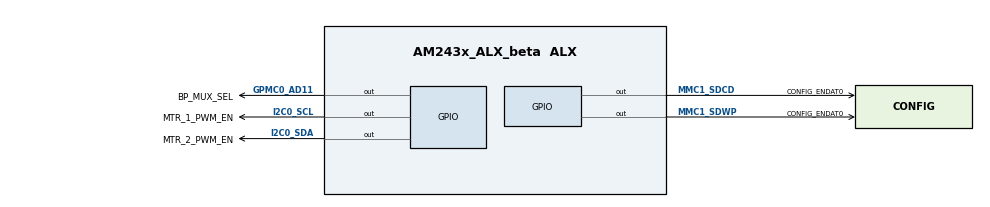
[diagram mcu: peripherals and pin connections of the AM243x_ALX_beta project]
/**
 * @cliArgs --device "AM243x_ALX_beta" --package "ALX" --part "ALX" --context "r5fss0-0" --product "MOTOR_CONTROL_SDK@09.01.00"
 * @versions {"tool":"1.19.0+3426"}
 */

/**
 * Import the modules used in this configuration.
 */
const epwm            = scripting.addModule("/drivers/epwm/epwm", {}, false);
const epwm1           = epwm.addInstance();
const epwm2           = epwm.addInstance();
const epwm3           = epwm.addInstance();
const gpio            = scripting.addModule("/drivers/gpio/gpio", {}, false);
const gpio1           = gpio.addInstance();
const gpio2           = gpio.addInstance();
const gpio3           = gpio.addInstance();
const ipc             = scripting.addModule("/drivers/ipc/ipc");
const mcspi           = scripting.addModule("/drivers/mcspi/mcspi", {}, false);
const mcspi1          = mcspi.addInstance();
const pruicss         = scripting.addModule("/drivers/pruicss/pruicss", {}, false);
const pruicss1        = pruicss.addInstance();
const debug_log       = scripting.addModule("/kernel/dpl/debug_log");
const mpu_armv7       = scripting.addModule("/kernel/dpl/mpu_armv7", {}, false);
const mpu_armv71      = mpu_armv7.addInstance();
const mpu_armv72      = mpu_armv7.addInstance();
const mpu_armv73      = mpu_armv7.addInstance();
const mpu_armv74      = mpu_armv7.addInstance();
const mpu_armv75      = mpu_armv7.addInstance();
const mpu_armv76      = mpu_armv7.addInstance();
const mpu_armv77      = mpu_armv7.addInstance();
const mpu_armv78      = mpu_armv7.addInstance();
const mpu_armv79      = mpu_armv7.addInstance();
const mpu_armv710     = mpu_armv7.addInstance();
const mpu_armv711     = mpu_armv7.addInstance();
const mpu_armv712     = mpu_armv7.addInstance();
const mpu_armv713     = mpu_armv7.addInstance();
const default_linker  = scripting.addModule("/memory_configurator/default_linker", {}, false);
const default_linker1 = default_linker.addInstance();
const general         = scripting.addModule("/memory_configurator/general", {}, false);
const general1        = general.addInstance();
const region          = scripting.addModule("/memory_configurator/region", {}, false);
const region1         = region.addInstance();
const section         = scripting.addModule("/memory_configurator/section", {}, false);
const section1        = section.addInstance();
const section2        = section.addInstance();
const section3        = section.addInstance();
const section4        = section.addInstance();
const section5        = section.addInstance();
const section6        = section.addInstance();
const section7        = section.addInstance();
const section8        = section.addInstance();
const section9        = section.addInstance();
const section10       = section.addInstance();
const section11       = section.addInstance();
const section12       = section.addInstance();
const section13       = section.addInstance();
const section14       = section.addInstance();
const section15       = section.addInstance();
const section16       = section.addInstance();
const section17       = section.addInstance();
const section18       = section.addInstance();
const section19       = section.addInstance();
const section20       = section.addInstance();
const endat           = scripting.addModule("/position_sense/endat", {}, false);
const endat1          = endat.addInstance();
const pru_ipc         = scripting.addModule("/pru_io/pru_ipc/pru_ipc", {}, false);
const pru_ipc1        = pru_ipc.addInstance();

/**
 * Write custom configuration values to the imported modules.
 */
epwm1.$name            = "EPWM0";
epwm1.EPWM.$assign     = "EHRPWM2";
epwm1.EPWM.SYNCO.$used = false;
epwm1.EPWM.SYNCI.$used = false;

epwm2.$name            = "EPWM1";
epwm2.EPWM.$assign     = "EHRPWM1";
epwm2.EPWM.SYNCO.$used = false;
epwm2.EPWM.SYNCI.$used = false;

epwm3.$name            = "EPWM2";
epwm3.EPWM.$assign     = "EHRPWM0";
epwm3.EPWM.SYNCO.$used = false;
epwm3.EPWM.SYNCI.$used = false;

gpio1.$name                = "MTR_1_PWM_EN";
gpio1.pinDir               = "OUTPUT";
gpio1.GPIO.gpioPin.$assign = "I2C0_SCL";

gpio2.$name                = "MTR_2_PWM_EN";
gpio2.pinDir               = "OUTPUT";
gpio2.GPIO.gpioPin.$assign = "I2C0_SDA";

gpio3.$name                = "BP_MUX_SEL";
gpio3.pinDir               = "OUTPUT";
gpio3.GPIO.gpioPin.$assign = "GPMC0_AD11";

ipc.r5fss0_1 = "notify";
ipc.r5fss1_0 = "notify";
ipc.r5fss1_1 = "NONE";
ipc.m4fss0_0 = "notify";

mcspi1.$name                 = "CONFIG_MCSPI0";
mcspi1.pinMode               = 3;
mcspi1.inputSelect           = "0";
mcspi1.dpe0                  = "DISABLE";
mcspi1.dpe1                  = "ENABLE";
mcspi1.intrEnable            = "POLLED";
mcspi1.SPI.$assign           = "SPI0";
mcspi1.mcspiChannel[0].$name = "CONFIG_MCSPI_CH0";
mcspi1.child.$name           = "drivers_mcspi_v0_mcspi_v0_template0";

const udma        = scripting.addModule("/drivers/udma/udma", {}, false);
const udma1       = udma.addInstance({}, false);
udma1.$name       = "CONFIG_UDMA0";
mcspi1.udmaDriver = udma1;

debug_log.enableCssLog = false;

mpu_armv71.$name             = "CONFIG_MPU_REGION0";
mpu_armv71.size              = 31;
mpu_armv71.attributes        = "Device";
mpu_armv71.accessPermissions = "Supervisor RD+WR, User RD";
mpu_armv71.allowExecute      = false;

mpu_armv72.$name             = "CONFIG_MPU_REGION1";
mpu_armv72.accessPermissions = "Supervisor RD+WR, User RD";
mpu_armv72.size              = 16;
mpu_armv72.attributes        = "NonCached";

mpu_armv73.$name             = "CONFIG_MPU_REGION2";
mpu_armv73.baseAddr          = 0x41010000;
mpu_armv73.accessPermissions = "Supervisor RD+WR, User RD";
mpu_armv73.size              = 16;
mpu_armv73.attributes        = "NonCached";

mpu_armv74.$name             = "CONFIG_MPU_REGION3";
mpu_armv74.accessPermissions = "Supervisor RD+WR, User RD";
mpu_armv74.baseAddr          = 0x70000000;
mpu_armv74.size              = 21;

mpu_armv75.$name        = "CONFIG_MPU_REGION4";
mpu_armv75.baseAddr     = 0x60000000;
mpu_armv75.size         = 28;
mpu_armv75.attributes   = "Device";
mpu_armv75.allowExecute = false;

mpu_armv76.$name        = "CONFIG_MPU_REGION5_GPIO";
mpu_armv76.baseAddr     = 0x600000;
mpu_armv76.size         = 19;
mpu_armv76.attributes   = "Device";
mpu_armv76.allowExecute = false;

mpu_armv77.$name        = "CONFIG_MPU_REGION6_ICSSG0";
mpu_armv77.baseAddr     = 0x30000000;
mpu_armv77.size         = 19;
mpu_armv77.allowExecute = false;
mpu_armv77.attributes   = "NonCached";

mpu_armv78.$name        = "CONFIG_MPU_REGION7_PWMs0_8";
mpu_armv78.baseAddr     = 0x23000000;
mpu_armv78.size         = 19;
mpu_armv78.attributes   = "NonCached";
mpu_armv78.allowExecute = false;

mpu_armv79.$name      = "CONFIG_MPU_REGION8_PWM9";
mpu_armv79.attributes = "NonCached";
mpu_armv79.size       = 16;
mpu_armv79.baseAddr   = 0x23080000;

mpu_armv710.$name        = "CONFIG_MPU_REGION9_OTHER_R5F_TCMB";
mpu_armv710.baseAddr     = 0x78500000;
mpu_armv710.size         = 15;
mpu_armv710.allowExecute = false;
mpu_armv710.attributes   = "NonCached";

mpu_armv711.$name        = "CONFIG_MPU_MSRAM_CTRLVARS";
mpu_armv711.baseAddr     = 0x701BFF00;
mpu_armv711.size         = 8;
mpu_armv711.allowExecute = false;

mpu_armv712.$name        = "CONFIG_MPU_MSRAM_NOCACHE";
mpu_armv712.size         = 16;
mpu_armv712.attributes   = "NonCached";
mpu_armv712.allowExecute = false;
mpu_armv712.baseAddr     = 0x701D0000;

mpu_armv713.$name        = "CONFIG_MPU_MSRAM_NOCACHE0";
mpu_armv713.baseAddr     = 0x701C0000;
mpu_armv713.size         = 16;
mpu_armv713.attributes   = "NonCached";
mpu_armv713.allowExecute = false;

default_linker1.$name = "memory_configurator_default_linker0";

general1.$name          = "CONFIG_GENERAL0";
general1.irq_stack_size = 8192;
general1.svc_stack_size = 8192;
general1.linker.$name   = "TIARMCLANG0";

region1.$name                                = "MEMORY_REGION_CONFIGURATION0";
region1.memory_region.create(19);
region1.memory_region[0].type                = "TCMA_R5F";
region1.memory_region[0].$name               = "R5F_VECS";
region1.memory_region[0].size                = 0x40;
region1.memory_region[0].auto                = false;
region1.memory_region[1].type                = "TCMA_R5F";
region1.memory_region[1].$name               = "R5F_TCMA";
region1.memory_region[1].size                = 0x7FC0;
region1.memory_region[1].auto                = false;
region1.memory_region[1].manualStartAddress  = 0x40;
region1.memory_region[2].type                = "TCMB_R5F";
region1.memory_region[2].$name               = "R5F_TCMB0_SDDF_0_0";
region1.memory_region[2].size                = 0x80;
region1.memory_region[2].auto                = false;
region1.memory_region[3].type                = "TCMB_R5F";
region1.memory_region[3].$name               = "R5F_TCMB0_SDDF_0_1";
region1.memory_region[3].size                = 0x80;
region1.memory_region[3].auto                = false;
region1.memory_region[3].manualStartAddress  = 0x41010080;
region1.memory_region[4].type                = "TCMB_R5F";
region1.memory_region[4].$name               = "R5F_TCMB0_ENC";
region1.memory_region[4].size                = 0x100;
region1.memory_region[4].auto                = false;
region1.memory_region[4].manualStartAddress  = 0x41010100;
region1.memory_region[5].type                = "TCMB_R5F";
region1.memory_region[5].$name               = "R5F_TCMB0_PDO";
region1.memory_region[5].size                = 0x100;
region1.memory_region[5].auto                = false;
region1.memory_region[5].manualStartAddress  = 0x41010200;
region1.memory_region[6].type                = "TCMB_R5F";
region1.memory_region[6].$name               = "R5F_TCMB0";
region1.memory_region[6].size                = 0x7D00;
region1.memory_region[6].auto                = false;
region1.memory_region[6].manualStartAddress  = 0x41010300;
region1.memory_region[7].$name               = "MSRAM1";
region1.memory_region[7].auto                = false;
region1.memory_region[7].manualStartAddress  = 0x70040000;
region1.memory_region[7].size                = 0x40000;
region1.memory_region[8].$name               = "MSRAM2";
region1.memory_region[8].auto                = false;
region1.memory_region[8].manualStartAddress  = 0x70080000;
region1.memory_region[8].size                = 0x40000;
region1.memory_region[9].$name               = "MSRAM_0_0";
region1.memory_region[9].auto                = false;
region1.memory_region[9].manualStartAddress  = 0x70140000;
region1.memory_region[9].size                = 0x40000;
region1.memory_region[10].$name              = "MSRAM_0_1";
region1.memory_region[10].auto               = false;
region1.memory_region[10].manualStartAddress = 0x70180000;
region1.memory_region[10].size               = 0x3FE00;
region1.memory_region[11].$name              = "MSRAM_1_0";
region1.memory_region[11].auto               = false;
region1.memory_region[11].manualStartAddress = 0x700C0000;
region1.memory_region[11].size               = 0x70000;
region1.memory_region[12].$name              = "MSRAM_CTRL_VARS_0_0";
region1.memory_region[12].auto               = false;
region1.memory_region[12].manualStartAddress = 0x701BFE00;
region1.memory_region[12].size               = 0x100;
region1.memory_region[13].$name              = "MSRAM_CTRL_VARS_0_1";
region1.memory_region[13].auto               = false;
region1.memory_region[13].manualStartAddress = 0x701BFF00;
region1.memory_region[13].size               = 0x100;
region1.memory_region[14].$name              = "MSRAM_NO_CACHE";
region1.memory_region[14].auto               = false;
region1.memory_region[14].manualStartAddress = 0x701C0000;
region1.memory_region[14].size               = 0x100;
region1.memory_region[15].$name              = "USER_SHM_MEM";
region1.memory_region[15].auto               = false;
region1.memory_region[15].manualStartAddress = 0x701D0000;
region1.memory_region[15].size               = 0x4000;
region1.memory_region[16].$name              = "LOG_SHM_MEM";
region1.memory_region[16].auto               = false;
region1.memory_region[16].manualStartAddress = 0x701D4000;
region1.memory_region[16].size               = 0x4000;
region1.memory_region[17].$name              = "RTOS_NORTOS_IPC_SHM_MEM";
region1.memory_region[17].auto               = false;
region1.memory_region[17].manualStartAddress = 0x701D8000;
region1.memory_region[17].size               = 0x8000;
region1.memory_region[18].type               = "CUSTOM_ALL";
region1.memory_region[18].$name              = "OTHER_R5F_TCMB0_PDO";
region1.memory_region[18].auto               = false;
region1.memory_region[18].manualStartAddress = 0x78500000;
region1.memory_region[18].size               = 0x100;

section1.$name                        = "Vector Table";
section1.load_memory                  = "R5F_VECS";
section1.group                        = false;
section1.output_section.create(1);
section1.output_section[0].$name      = ".vectors";
section1.output_section[0].palignment = true;

section2.$name                        = "Text Segments";
section2.load_memory                  = "MSRAM_0_0";
section2.output_section.create(5);
section2.output_section[0].$name      = ".text.hwi";
section2.output_section[0].palignment = true;
section2.output_section[1].$name      = ".text.cache";
section2.output_section[1].palignment = true;
section2.output_section[2].$name      = ".text.mpu";
section2.output_section[2].palignment = true;
section2.output_section[3].$name      = ".text.boot";
section2.output_section[3].palignment = true;
section2.output_section[4].$name      = ".text:abort";
section2.output_section[4].palignment = true;

section3.$name                        = "Code and Read-Only Data";
section3.load_memory                  = "MSRAM_0_0";
section3.output_section.create(2);
section3.output_section[0].$name      = ".text";
section3.output_section[0].palignment = true;
section3.output_section[1].$name      = ".rodata";
section3.output_section[1].palignment = true;

section4.$name                        = "Data Segment";
section4.load_memory                  = "MSRAM_0_0";
section4.output_section.create(1);
section4.output_section[0].$name      = ".data";
section4.output_section[0].palignment = true;

section5.$name                                   = "Memory Segments";
section5.load_memory                             = "MSRAM_0_0";
section5.output_section.create(3);
section5.output_section[0].$name                 = ".bss";
section5.output_section[0].palignment            = true;
section5.output_section[0].output_sections_start = "__BSS_START";
section5.output_section[0].output_sections_end   = "__BSS_END";
section5.output_section[1].$name                 = ".sysmem";
section5.output_section[1].palignment            = true;
section5.output_section[2].$name                 = ".stack";
section5.output_section[2].palignment            = true;

section6.$name                                    = "Stack Segments";
section6.load_memory                              = "MSRAM_0_0";
section6.output_section.create(5);
section6.output_section[0].$name                  = ".irqstack";
section6.output_section[0].output_sections_start  = "__IRQ_STACK_START";
section6.output_section[0].output_sections_end    = "__IRQ_STACK_END";
section6.output_section[0].input_section.create(1);
section6.output_section[0].input_section[0].$name = ". = . + __IRQ_STACK_SIZE;";
section6.output_section[1].$name                  = ".fiqstack";
section6.output_section[1].output_sections_start  = "__FIQ_STACK_START";
section6.output_section[1].output_sections_end    = "__FIQ_STACK_END";
section6.output_section[1].input_section.create(1);
section6.output_section[1].input_section[0].$name = ". = . + __FIQ_STACK_SIZE;";
section6.output_section[2].$name                  = ".svcstack";
section6.output_section[2].output_sections_start  = "__SVC_STACK_START";
section6.output_section[2].output_sections_end    = "__SVC_STACK_END";
section6.output_section[2].input_section.create(1);
section6.output_section[2].input_section[0].$name = ". = . + __SVC_STACK_SIZE;";
section6.output_section[3].$name                  = ".abortstack";
section6.output_section[3].output_sections_start  = "__ABORT_STACK_START";
section6.output_section[3].output_sections_end    = "__ABORT_STACK_END";
section6.output_section[3].input_section.create(1);
section6.output_section[3].input_section[0].$name = ". = . + __ABORT_STACK_SIZE;";
section6.output_section[4].$name                  = ".undefinedstack";
section6.output_section[4].output_sections_start  = "__UNDEFINED_STACK_START";
section6.output_section[4].output_sections_end    = "__UNDEFINED_STACK_END";
section6.output_section[4].input_section.create(1);
section6.output_section[4].input_section[0].$name = ". = . + __UNDEFINED_STACK_SIZE;";

section7.$name                        = "Initialization and Exception Handling";
section7.load_memory                  = "MSRAM_0_0";
section7.output_section.create(3);
section7.output_section[0].$name      = ".ARM.exidx";
section7.output_section[0].palignment = true;
section7.output_section[1].$name      = ".init_array";
section7.output_section[1].palignment = true;
section7.output_section[2].$name      = ".fini_array";
section7.output_section[2].palignment = true;

section8.$name                       = "User Shared Memory";
section8.type                        = "NOLOAD";
section8.load_memory                 = "USER_SHM_MEM";
section8.group                       = false;
section8.output_section.create(1);
section8.output_section[0].$name     = ".bss.user_shared_mem";
section8.output_section[0].alignment = 0;

section9.$name                       = "Log Shared Memory";
section9.load_memory                 = "LOG_SHM_MEM";
section9.type                        = "NOLOAD";
section9.group                       = false;
section9.output_section.create(1);
section9.output_section[0].$name     = ".bss.log_shared_mem";
section9.output_section[0].alignment = 0;

section10.$name                       = "IPC Shared Memory";
section10.type                        = "NOLOAD";
section10.load_memory                 = "RTOS_NORTOS_IPC_SHM_MEM";
section10.group                       = false;
section10.output_section.create(1);
section10.output_section[0].$name     = ".bss.ipc_vring_mem";
section10.output_section[0].alignment = 0;

section11.$name                       = "SDFM Samples";
section11.group                       = false;
section11.load_memory                 = "R5F_TCMB0_SDDF_0_0";
section11.output_section.create(1);
section11.output_section[0].$name     = ".gSddfChSampsRaw";
section11.output_section[0].alignment = 4;

section12.$name                       = "TX Data";
section12.group                       = false;
section12.load_memory                 = "R5F_TCMB0_PDO";
section12.output_section.create(1);
section12.output_section[0].$name     = ".gTxDataSection";
section12.output_section[0].alignment = 4;

section13.$name                       = "RX Data";
section13.group                       = false;
section13.load_memory                 = "OTHER_R5F_TCMB0_PDO";
section13.output_section.create(1);
section13.output_section[0].$name     = ".gRxDataSection";
section13.output_section[0].alignment = 4;

section14.$name                       = "Debug Buffer 1";
section14.group                       = false;
section14.load_memory                 = "MSRAM1";
section14.output_section.create(1);
section14.output_section[0].$name     = ".gDebugBuff1";
section14.output_section[0].alignment = 4;

section15.group                       = false;
section15.$name                       = "Debug Buffer 2";
section15.load_memory                 = "MSRAM2";
section15.output_section.create(1);
section15.output_section[0].alignment = 4;
section15.output_section[0].$name     = ".gDebugBuff2";

section16.$name                       = "ENDAT Channel Info";
section16.group                       = false;
section16.load_memory                 = "R5F_TCMB0_ENC";
section16.output_section.create(1);
section16.output_section[0].$name     = ".gEnDatChInfo";
section16.output_section[0].alignment = 4;

section17.$name                        = "Critical Code and Data";
section17.group                        = false;
section17.load_memory                  = "R5F_TCMB0";
section17.output_section.create(2);
section17.output_section[0].$name      = ".critical_code";
section17.output_section[0].alignment  = 4;
section17.output_section[0].palignment = true;
section17.output_section[1].$name      = ".critical_data";
section17.output_section[1].palignment = true;

section18.$name                        = "Control Variables";
section18.group                        = false;
section18.load_memory                  = "MSRAM_CTRL_VARS_0_0";
section18.output_section.create(1);
section18.output_section[0].$name      = ".gCtrlVars";
section18.output_section[0].palignment = true;

section19.$name                        = "User Shared Memory 2";
section19.group                        = false;
section19.load_memory                  = "USER_SHM_MEM";
section19.output_section.create(2);
section19.output_section[0].$name      = ".gSharedPrivStep";
section19.output_section[0].palignment = true;
section19.output_section[1].$name      = ".gSharedPruHandle";
section19.output_section[1].palignment = true;

section20.$name                        = "No Cache Memory";
section20.group                        = false;
section20.load_memory                  = "MSRAM_NO_CACHE";
section20.output_section.create(1);
section20.output_section[0].$name      = ".gEtherCatCia402";
section20.output_section[0].alignment  = 4;
section20.output_section[0].palignment = true;

endat1.$name                        = "CONFIG_ENDAT0";
endat1.Channel_2                    = true;
endat1.Booster_Pack                 = true;
endat1.Multi_Channel_Load_Share     = true;
endat1.PRU_ICSSG0_PRU.$assign       = "PRU_ICSSG0_PRU1";
endat1.ENC1_EN.$name                = "ENC1_EN";
endat1.ENC1_EN.GPIO.$assign         = "GPIO1";
endat1.ENC1_EN.GPIO.gpioPin.pu_pd   = "pu";
endat1.ENC1_EN.GPIO.gpioPin.rx      = false;
endat1.ENC1_EN.GPIO.gpioPin.$assign = "MMC1_SDWP";
endat1.ENC2_EN.$name                = "ENC2_EN";
endat1.ENC2_EN.GPIO.$assign         = "GPIO1";
endat1.ENC2_EN.GPIO.gpioPin.pu_pd   = "pu";
endat1.ENC2_EN.GPIO.gpioPin.rx      = false;
endat1.ENC2_EN.GPIO.gpioPin.$assign = "MMC1_SDCD";

pruicss1.$name                                                                    = "CONFIG_PRU_ICSS0";
endat1.pru                                                                        = pruicss1;
pruicss1.coreClk                                                                  = 300000000;
pruicss1.iepClk                                                                   = 300000000;
pruicss1.AdditionalICSSSettings[0].$name                                          = "CONFIG_PRU_ICSS_IO0";
pruicss1.AdditionalICSSSettings[0].PruGPIO.create(1);
pruicss1.AdditionalICSSSettings[0].PruGPIO[0].$name                               = "CONFIG_PRU_ICSS_GPIO0";
pruicss1.AdditionalICSSSettings[0].PruGPIO[0].PRU_ICSSG0_PRU.GPI1.$used           = true;
pruicss1.AdditionalICSSSettings[0].PruGPIO[0].PRU_ICSSG0_PRU.GPI11.$used          = true;
pruicss1.AdditionalICSSSettings[0].PruGPIO[0].PRU_ICSSG0_PRU.GPI16.$used          = true;
pruicss1.AdditionalICSSSettings[0].PruGPIO[0].PRU_ICSSG0_PRU.GPI18.$used          = true;
pruicss1.AdditionalICSSSettings[0].PruGPIO[0].PRU_ICSSG0_PRU.GPI19.rx             = false;
pruicss1.AdditionalICSSSettings[0].PruGPIO[0].PRU_ICSSG0_PRU.GPI3.$used           = true;
pruicss1.AdditionalICSSSettings[0].PruGPIO[0].PRU_ICSSG0_PRU.GPI5.$used           = true;
pruicss1.AdditionalICSSSettings[0].PruGPIO[0].PRU_ICSSG0_PRU.GPI7.$used           = true;
pruicss1.AdditionalICSSSettings[0].PruGPIO[0].PRU_ICSSG0_PRU.GPI8.$used           = true;
pruicss1.AdditionalICSSSettings[0].PruIepIO.create(1);
pruicss1.AdditionalICSSSettings[0].PruIepIO[0].$name                              = "CONFIG_PRU_ICSS_IEP_IO0";
pruicss1.AdditionalICSSSettings[0].PruIepIO[0].PRU_ICSSG0_IEP.EDC_SYNC_OUT0.$used = true;
pruicss1.AdditionalICSSSettings[0].PruIepIO[0].PRU_ICSSG0_IEP.EDC_SYNC_OUT1.$used = true;

pru_ipc1.$name               = "CONFIG_PRU_IPC0";
pru_ipc1.rxIntcMapping.$name = "CONFIG_ICSS0_INTC_MAPPING0";

/**
 * Pinmux solution for unlocked pins/peripherals. This ensures that minor changes to the automatic solver in a future
 * version of the tool will not impact the pinmux you originally saw.  These lines can be completely deleted in order to
 * re-solve from scratch.
 */
epwm1.EPWM.A.$suggestSolution                                                                = "GPMC0_AD8";
epwm1.EPWM.B.$suggestSolution                                                                = "GPMC0_AD9";
epwm2.EPWM.A.$suggestSolution                                                                = "GPMC0_AD5";
epwm2.EPWM.B.$suggestSolution                                                                = "GPMC0_AD6";
epwm3.EPWM.A.$suggestSolution                                                                = "GPMC0_AD3";
epwm3.EPWM.B.$suggestSolution                                                                = "GPMC0_AD4";
gpio1.GPIO.$suggestSolution                                                                  = "GPIO1";
gpio2.GPIO.$suggestSolution                                                                  = "GPIO1";
gpio3.GPIO.$suggestSolution                                                                  = "GPIO0";
mcspi1.SPI.CLK.$suggestSolution                                                              = "SPI0_CLK";
mcspi1.SPI.D0.$suggestSolution                                                               = "SPI0_D0";
mcspi1.SPI.D1.$suggestSolution                                                               = "SPI0_D1";
endat1.PRU_ICSSG0_PRU.GPO2.$suggestSolution                                                  = "PRG0_PRU1_GPO2";
endat1.PRU_ICSSG0_PRU.GPO1.$suggestSolution                                                  = "PRG0_PRU1_GPO1";
endat1.PRU_ICSSG0_PRU.GPO0.$suggestSolution                                                  = "PRG0_PRU1_GPO0";
endat1.PRU_ICSSG0_PRU.GPI13.$suggestSolution                                                 = "PRG0_PRU1_GPO13";
endat1.PRU_ICSSG0_PRU.GPO8.$suggestSolution                                                  = "PRG0_PRU1_GPO8";
endat1.PRU_ICSSG0_PRU.GPO12.$suggestSolution                                                 = "PRG0_PRU1_GPO12";
endat1.PRU_ICSSG0_PRU.GPO6.$suggestSolution                                                  = "PRG0_PRU1_GPO6";
endat1.PRU_ICSSG0_PRU.GPI11.$suggestSolution                                                 = "PRG0_PRU1_GPO11";
pruicss1.AdditionalICSSSettings[0].PruGPIO[0].PRU_ICSSG0_PRU.$suggestSolution                = "PRU_ICSSG0_PRU0";
pruicss1.AdditionalICSSSettings[0].PruGPIO[0].PRU_ICSSG0_PRU.GPI1.$suggestSolution           = "PRG0_PRU0_GPO1";
pruicss1.AdditionalICSSSettings[0].PruGPIO[0].PRU_ICSSG0_PRU.GPI11.$suggestSolution          = "PRG0_PRU0_GPO11";
pruicss1.AdditionalICSSSettings[0].PruGPIO[0].PRU_ICSSG0_PRU.GPI16.$suggestSolution          = "PRG0_PRU0_GPO16";
pruicss1.AdditionalICSSSettings[0].PruGPIO[0].PRU_ICSSG0_PRU.GPI18.$suggestSolution          = "PRG0_PRU0_GPO18";
pruicss1.AdditionalICSSSettings[0].PruGPIO[0].PRU_ICSSG0_PRU.GPI3.$suggestSolution           = "PRG0_PRU0_GPO3";
pruicss1.AdditionalICSSSettings[0].PruGPIO[0].PRU_ICSSG0_PRU.GPI5.$suggestSolution           = "PRG0_PRU0_GPO5";
pruicss1.AdditionalICSSSettings[0].PruGPIO[0].PRU_ICSSG0_PRU.GPI7.$suggestSolution           = "PRG0_PRU0_GPO7";
pruicss1.AdditionalICSSSettings[0].PruGPIO[0].PRU_ICSSG0_PRU.GPI8.$suggestSolution           = "PRG0_PRU0_GPO8";
pruicss1.AdditionalICSSSettings[0].PruIepIO[0].PRU_ICSSG0_IEP.$suggestSolution               = "PRU_ICSSG0_IEP0";
pruicss1.AdditionalICSSSettings[0].PruIepIO[0].PRU_ICSSG0_IEP.EDC_SYNC_OUT0.$suggestSolution = "PRG0_PRU0_GPO19";
pruicss1.AdditionalICSSSettings[0].PruIepIO[0].PRU_ICSSG0_IEP.EDC_SYNC_OUT1.$suggestSolution = "PRG0_PRU0_GPO17";
